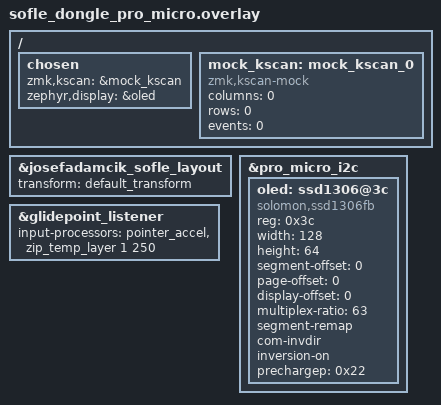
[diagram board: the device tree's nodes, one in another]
// #include <dt-bindings/zmk/matrix_transform.h>
// #include <layouts/josefadamcik/sofle.dtsi>
#include "sofle.dtsi"
#include "split_inputs.dtsi"
#include <input/processors.dtsi>

&josefadamcik_sofle_layout {
    transform = <&default_transform>;
};

/ {
    chosen {
        zmk,kscan = &mock_kscan;
        zephyr,display = &oled;
    };

    mock_kscan: mock_kscan_0 {
        compatible = "zmk,kscan-mock";
        // wakeup-source;
        columns = <0>;
        rows = <0>;
        events = <0>;
    };

};

&pro_micro_i2c {
    status = "okay";

    oled: ssd1306@3c {
        compatible = "solomon,ssd1306fb";
        reg = <0x3c>;
        width = <128>;
        height = <64>;
        segment-offset = <0>;
        page-offset = <0>;
        display-offset = <0>;
        multiplex-ratio = <63>;
        segment-remap;
        com-invdir;
        inversion-on;
        prechargep = <0x22>;
    };
};

&glidepoint_listener {
    status = "okay";
    input-processors = <
        &pointer_accel
        &zip_temp_layer 1 250
	>;
};

/*
// 128x64 OLED
&pro_micro_i2c {
    status = "okay";

    oled: ssd1306@3c {
        compatible = "solomon,ssd1306fb";
        reg = <0x3c>;
        width = <128>;
        height = <64>;
        segment-offset = <0>;
        page-offset = <0>;
        display-offset = <0>;
        multiplex-ratio = <63>;
        segment-remap;
        com-invdir;
        inversion-on;
        prechargep = <0x22>;
    };
};
// 128x32 OLED
&pro_micro_i2c {
    status = "okay";

    oled: ssd1306@3c {
        compatible = "solomon,ssd1306fb";
        reg = <0x3c>;
        width = <128>;
        height = <32>;
        segment-offset = <0>;
        page-offset = <0>;
        display-offset = <0>;
        multiplex-ratio = <31>;
        segment-remap;
        com-invdir;
        com-sequential;
        inversion-on;
        prechargep = <0x22>;
    };
};

// 128x64 OLED model sh1106

&pro_micro_i2c {
    status = "okay";
    oled: sh1106@3c {
        compatible = "sinowealth,sh1106";
        reg = <0x3c>;
        width = <129>;
        height = <64>;
        segment-offset = <1>;
        page-offset = <0>;
        display-offset = <0>;
        multiplex-ratio = <63>;
        segment-remap;
        com-invdir;
        inversion-on;
        prechargep = <0x22>;
        };
};

// 128x128 OLED model sh1107
&pro_micro_i2c {
    status = "okay";
    oled: sh1106@3c {
        compatible = "sinowealth,sh1106";
        reg = <0x3c>;
        width = <120>;
        height = <128>;
        segment-offset = <0>;
        page-offset = <0>;
        display-offset = <0>;
        multiplex-ratio = <119>;
        segment-remap;
        com-invdir;
        inversion-on;
        prechargep = <0x22>;
        };
};
*/
